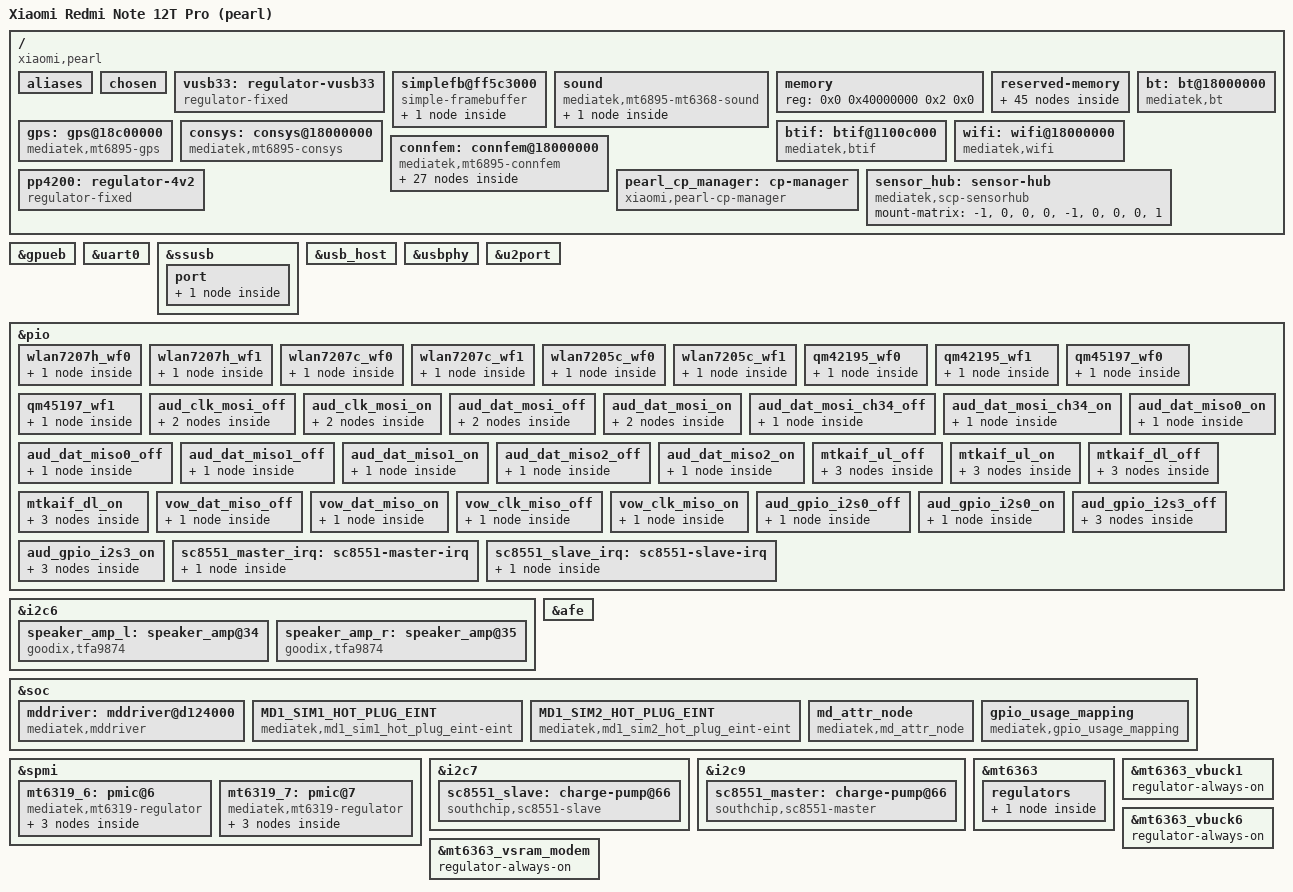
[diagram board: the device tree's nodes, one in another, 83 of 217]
// SPDX-License-Identifier: GPL-2.0 OR MIT
/*
 * MediaTek MT6896 (Dimensity 8200) Xiaomi Redmi Note 12T Pro board.
 * The DTS keeps the mt6895 platform-family naming used by its siblings.
 *
 * Codename: pearl (Xiaomi Redmi Note 12T Pro).
 *
 * Reserved-memory, regulators and rails follow the captured bootloader (LK) layout;
 * the embedded DTB replaces LK's but the memory map must stay identical.
 */

/dts-v1/;
#include "mt6895.dtsi"
#include <dt-bindings/input/input.h>
#include <dt-bindings/gpio/gpio.h>

/ {
	model = "Xiaomi Redmi Note 12T Pro (pearl)";
	chassis-type = "handset";
	compatible = "xiaomi,pearl", "mediatek,mt6895";

	#address-cells = <2>;
	#size-cells = <2>;

	aliases {
		serial0 = &uart0;
		/* match stock bus numbering so mt6375 etc. land on i2c-5 */
		i2c1 = &i2c1;
		i2c5 = &i2c5;
		i2c6 = &i2c6;
		i2c7 = &i2c7;
		i2c9 = &i2c9;
	};

	chosen {
		/*
		 * PEARL cmdline: setup.c re-reads /chosen/bootargs from THIS
		 * embedded DTB (early_init_dt_scan_chosen) because LK passes its
		 * own baked-in cmdline (setup_machine_fdt captured it before the
		 * DTB override) and ignores boot.img / vendor_boot cmdlines.
		 * printk.devkmsg=on: /dev/kmsg writes default to a 10-per-5s
		 * ratelimit that was silently dropping cinit's bursty GPT/diag
		 * output (also patched in kernel/printk/printk.c default).
		 * NOTE: console=ttyGS0 is DELIBERATELY absent — its CON_PRINTBUFFER
		 * console kept replaying the whole ring (USB re-enumeration),
		 * looping the log and stalling boot. The cinit shell still works
		 * (it writes directly to /dev/ttyGS0, no console param needed).
		 */
		bootargs = "8250.nr_uarts=4 clk_ignore_unused console=tty0 printk.devkmsg=on log_buf_len=2M";
		/*
		 * LK injects this tag into its FDT; our embedded-DTB override would
		 * lose it. Values dumped from the working Android device:
		 * struct tag_videolfb { u64 fb_base; u32 islcmfound; u32 fps;
		 *                      u32 vram; char lcmname[]; } (LE)
		 * fb_base=0xfe14f000 (framebuffer region start), islcmfound=1,
		 * fps=6060 (x100), vram=0x1eb0000, lcmname="l16_36_02_0b_dsc_vdo_lcm_drv".
		 * Without it, mtk_crtc_fill_fb_para() fails and the LK framebuffer is
		 * never inserted into the display IOMMU -> OVL fetch fault -> RDMA
		 * underflow -> display pipeline stalls after the LK frame.
		 */
		atag,videolfb = [00 f0 14 fe 00 00 00 00 01 00 00 00 ac 17 00 00
				 00 00 eb 01 6c 31 36 5f 33 36 5f 30 32 5f 30 62
				 5f 64 73 63 5f 76 64 6f 5f 6c 63 6d 5f 64 72 76
				 00 60 ff 50];
	};

	/* USB gadget 3.3V rail (mtu3 requires vusb33-supply; LK powers it) */
	vusb33: regulator-vusb33 {
		compatible = "regulator-fixed";
		regulator-name = "vusb33";
		regulator-min-microvolt = <3300000>;
		regulator-max-microvolt = <3300000>;
		regulator-always-on;
	};

	/*
	 * simple-framebuffer left behind by LK. Placed at root level (not under
	 * /chosen) because LK rewrites /chosen and would drop it.
	 * Address = the actual LK scanout layer (mt_disp_config_fb_layer =
	 * 0xff5c3000), which sits inside the reserved mblock-12-framebuffer
	 * region (0xfe14f000..0xfffff000). fbcon draws into the live LK buffer.
	 */
	simplefb@ff5c3000 {
		compatible = "simple-framebuffer";
		/* frame = stride(4352) * height(2460) = 0xa35c00; stays inside the
		 * no-map mblock-12-framebuffer region (0xfe14f000..0xfffff000) */
		reg = <0x0 0xff5c3000 0x0 0xa3c000>;
		width = <1080>;
		height = <2460>;
		stride = <(1088 * 4)>;
		format = "a8r8g8b8";
		panel = <&fb_panel>;

		fb_panel: fb-panel {
			width-mm = <75>;
			height-mm = <166>;
		};
	};

	sound {
		compatible = "mediatek,mt6895-mt6368-sound";
		mediatek,platform = <&afe>;
		mediatek,headset-codec = <&mt6368codec>;
		/* I2S3 out to smart amps; I2S0 echo reference in */
		mediatek,spk-i2s = <3 9>;

		mediatek,speaker-codec {
			sound-dai = <&speaker_amp_l>, <&speaker_amp_r>;
		};
	};

	memory {
		device_type = "memory";
		reg = <0x0 0x40000000 0x2 0x0>;
	};

	reserved-memory {
		#address-cells = <2>;
		#size-cells = <2>;
		ranges;

		/*
		 * Full MT6895 reserved-memory layout, taken verbatim from the
		 * live device tree (/sys/firmware/fdt) of the running stock
		 * Android build. These regions are owned by ATF/TEE/SCP/SSPM,
		 * modem, GPU and the display; the kernel MUST NOT allocate from
		 * them or early boot crashes on memory corruption.
		 */

		wifi_reserved: mblock-45-shared-dma-pool_wifi-reserve-memory_dma {
			reg = <0x00 0xbd000000 0x00 0x1400000>;
			no-map;
			compatible = "shared-dma-pool";
		};
		consys_reserved: mblock-44-consys_emi_reserved {
			reg = <0x00 0x8e500000 0x00 0x800000>;
			no-map;
			compatible = "mediatek,consys_emi_reserved";
		};
		mblock-43-sspm_ap-shared {
			reg = <0x00 0x7c4f0000 0x00 0x110000>;
			no-map;
			compatible = "mediatek,sspm_ap-shared";
		};
		mblock-42-consys_gps_emi {
			reg = <0x00 0x7cf00000 0x00 0x100000>;
			no-map;
			compatible = "mediatek,consys_gps_emi";
		};
		mblock-41-adsp_shared_reserved {
			reg = <0x00 0xf8000000 0x00 0x660000>;
			no-map;
			compatible = "mediatek,adsp_shared_reserved";
		};
		mblock-40-me_vcp_reserved {
			reg = <0x00 0xbee00000 0x00 0x800000>;
			no-map;
			compatible = "mediatek,me_vcp_reserved";
		};
		mblock-39-me_GPUmputab_PMA {
			reg = <0x00 0x78c00000 0x00 0x1400000>;
			no-map;
			compatible = "mediatek,me_GPUmputab_PMA";
		};
		mblock-38-me_GPUEB_SHARED {
			reg = <0x00 0x7c600000 0x00 0x200000>;
			no-map;
			compatible = "mediatek,me_GPUEB_SHARED";
		};
		mblock-37-adsp_image_reserved {
			reg = <0x00 0x7a000000 0x00 0x1230000>;
			no-map;
			compatible = "mediatek,adsp_image_reserved";
		};
		mblock-36-ap_md_c_smem {
			reg = <0x00 0x8a000000 0x00 0x2360000>;
			no-map;
			compatible = "mediatek,ap_md_c_smem";
		};
		mblock-35-ap_md_nc_smem {
			reg = <0x00 0x8e000000 0x00 0x120000>;
			no-map;
			compatible = "mediatek,ap_md_nc_smem";
		};
		mblock-34-md_mem_usage {
			reg = <0x00 0xed6e0000 0x00 0x920000>;
			no-map;
			compatible = "mediatek,md_mem_usage";
		};
		mblock-33-md_mem_usage {
			reg = <0x00 0xd4000000 0x00 0x7870000>;
			no-map;
			compatible = "mediatek,md_mem_usage";
		};
		mblock-32-md_mem_usage {
			reg = <0x00 0xd3000000 0x00 0x240000>;
			no-map;
			compatible = "mediatek,md_mem_usage";
		};
		mblock-31-md_mem_usage {
			reg = <0x00 0xd0000000 0x00 0x2710000>;
			no-map;
			compatible = "mediatek,md_mem_usage";
		};
		mblock-30-ccci_tag_mem {
			reg = <0x00 0xbf6f0000 0x00 0x10000>;
			no-map;
			compatible = "mediatek,ccci_tag_mem";
		};
		mblock-29-apu_apusys-rv_aee-coredump {
			reg = <0x00 0x8ed90000 0x00 0x270000>;
			no-map;
			compatible = "mediatek,apu_apusys-rv_aee-coredump";
		};
		mblock-28-apu_apusys-rv_secure {
			reg = <0x00 0x8f900000 0x00 0x700000>;
			no-map;
			compatible = "mediatek,apu_apusys-rv_secure";
		};
		mblock-27-apu_mvpu_algo {
			reg = <0x00 0xbf700000 0x00 0x200000>;
			compatible = "mediatek,apu_mvpu_algo";
		};
		mblock-26-mm_ccu_reserved {
			reg = <0x00 0x80000000 0x00 0x100000>;
			no-map;
			compatible = "mediatek,mm_ccu_reserved";
		};
		mblock-25-reserve-memory-scp_share {
			reg = <0x00 0x8f000000 0x00 0x6a2000>;
			no-map;
			compatible = "mediatek,reserve-memory-scp_share";
		};
		mblock-24-SCP-reserved {
			reg = <0x00 0xbf900000 0x00 0x500000>;
			no-map;
			compatible = "mediatek,SCP-reserved";
		};
		mblock-23-platform-debug_dfdmcu_dump {
			reg = <0x00 0xfd000000 0x00 0x280000>;
			no-map;
			compatible = "mediatek,platform-debug_dfdmcu_dump";
		};
		mblock-22-crypto_hw {
			reg = <0x00 0x48401000 0x00 0x1000>;
			no-map;
			compatible = "mediatek,crypto_hw";
		};
		mblock-21-security_tee_ree {
			reg = <0x02 0x3f000000 0x00 0xc00000>;
			no-map;
			compatible = "mediatek,security_tee_ree";
		};
		mblock-20-security_tee_log {
			reg = <0x02 0x3fc00000 0x00 0x20000>;
			no-map;
			compatible = "mediatek,security_tee_log";
		};
		mblock-19-tee-reserved {
			reg = <0x00 0x70000000 0x00 0x6000000>;
			no-map;
			compatible = "mediatek,tee-reserved";
		};
		mblock-18-tee-secmem {
			reg = <0x00 0x7c800000 0x00 0x700000>;
			no-map;
			compatible = "mediatek,tee-secmem";
		};
		mblock-17-MCUPM-reserved {
			reg = <0x00 0x7f300000 0x00 0x100000>;
			no-map;
			compatible = "mediatek,MCUPM-reserved";
		};
		mblock-16-SSPM-reserved {
			reg = <0x00 0x7fe3f000 0x00 0x180000>;
			no-map;
			compatible = "mediatek,SSPM-reserved";
		};
		mblock-15-BL31-reserved {
			reg = <0x00 0x48200000 0x00 0x200000>;
			no-map;
			compatible = "mediatek,BL31-reserved";
		};
		mblock-14-platform_mtksmmu_protpgd {
			reg = <0x00 0x7d000000 0x00 0x2200000>;
			no-map;
			compatible = "mediatek,platform_mtksmmu_protpgd";
		};
		mblock-13-me_cmdq_reserved {
			reg = <0x02 0x3fe00000 0x00 0x100000>;
			no-map;
			compatible = "mediatek,me_cmdq_reserved";
		};
		mblock-12-framebuffer {
			reg = <0x00 0xfe14f000 0x00 0x1eb0000>;
			/*
			 * no-map: this region (which contains the live LK scanout
			 * framebuffer at 0xff5c3000) must be excluded from the
			 * kernel's RAM map. Otherwise simplefb's
			 * request_mem_region()/ioremap() fail (-ENOMEM, "cannot
			 * reserve video memory" / ioremap_p2p WARN).
			 */
			no-map;
			compatible = "mediatek,framebuffer";
		};
		mblock-11-aee_lk {
			reg = <0x00 0x50700000 0x00 0x800000>;
			compatible = "mediatek,aee_lk";
		};
		mblock-10-minirdump {
			reg = <0x00 0x48170000 0x00 0x10000>;
			no-map;
			compatible = "mediatek,minirdump";
		};
		mblock-8-aee_debug_kinfo {
			reg = <0x00 0x48080000 0x00 0x10000>;
			no-map;
			compatible = "mediatek,aee_debug_kinfo";
		};
		mblock-7-atf-log-reserved {
			reg = <0x00 0xbfe00000 0x00 0x200000>;
			no-map;
			compatible = "mediatek,atf-log-reserved";
		};
		mblock-6-log_store {
			reg = <0x00 0x7ffbf000 0x00 0x40000>;
			compatible = "mediatek,log_store";
		};
		mblock-5-gz-log {
			reg = <0x00 0x7f200000 0x00 0x41000>;
			compatible = "mediatek,gz-log";
		};
		mblock-4-unmap2 {
			reg = <0x00 0x7f400000 0x00 0x400000>;
			no-map;
			compatible = "mediatek,unmap2";
		};
		mblock-3-gz {
			reg = <0x00 0x7f800000 0x00 0x600000>;
			no-map;
			compatible = "mediatek,gz";
		};
		mblock-2-emi_mbist_buf {
			reg = <0x00 0x7ffff000 0x00 0x1000>;
			no-map;
			compatible = "mediatek,emi_mbist_buf";
		};
		mblock-1-dramc-rk0 {
			reg = <0x02 0x3fffe000 0x00 0x2000>;
			no-map;
			compatible = "mediatek,dramc-rk0";
		};
		/* pstore/ramoops, matches the downstream Android config */
		ramoops@48090000 {
			compatible = "ramoops";
			reg = <0x00 0x48090000 0x00 0xe0000>;
			record-size = <0x20000>;
			console-size = <0x40000>;
			pmsg-size = <0x10000>;
			ecc-size = <0>;
			no-map;
		};
	};

	/* GPS (GNSS) —— 连接子系统（MT6637 a-die）里的 GPS 引擎。
	 * 数值来源：厂商 mt6895.dts 的 gps@18c00000；emi-addr 用 pearl 自己的
	 * mblock-42-consys_gps_emi（0x7cf00000, 1MiB）——LK 不会改写我们的内嵌 DTB，
	 * 所以 emi-addr 必须写死，不能像厂商那样留 0。
	 * 中断 528..534 与对照机 yuechu（同代 MT6895）完全一致。
	 */
	gps: gps@18c00000 {
		compatible = "mediatek,mt6895-gps";
		reg = <0x00 0x18000000 0x00 0x100000>,
		      <0x00 0x18c00000 0x00 0x100000>,
		      <0x00 0x1c000000 0x00 0x4>,
		      <0x00 0x1c805028 0x00 0x4>,
		      <0x00 0x1c805030 0x00 0x4>,
		      <0x00 0x1c8050cc 0x00 0x28>;
		reg-names = "conn_infra_base", "conn_gps_base",
			    "status_dummy_cr", "tia2_gps_on",
			    "tia2_gps_rc_sel", "tia2_gps_debug";
		interrupt-parent = <&gic>;
		interrupts = <GIC_SPI 528 IRQ_TYPE_LEVEL_HIGH 0>,
			     <GIC_SPI 529 IRQ_TYPE_LEVEL_HIGH 0>,
			     <GIC_SPI 530 IRQ_TYPE_LEVEL_HIGH 0>,
			     <GIC_SPI 531 IRQ_TYPE_LEVEL_HIGH 0>,
			     <GIC_SPI 532 IRQ_TYPE_LEVEL_HIGH 0>,
			     <GIC_SPI 533 IRQ_TYPE_LEVEL_HIGH 0>,
			     <GIC_SPI 534 IRQ_TYPE_LEVEL_HIGH 0>;
		emi-connac-ver = <2>;
		emi-addr = <0x7cf00000>;
		emi-size = <0x100000>;
		emi-alignment = <0x100000>;
		emi-max-addr = <0x80000000>;
		status = "okay";
	};

	/* MediaTek CONNAC2X2 SOC7_0 connectivity: consys / wifi / connfem.
	 * Nodes and properties copied from downstream mt6895.dts and
	 * cust_mt6895_connfem.dtsi.  memory-region references are added so the
	 * downstream fullmac driver can find the reserved EMI/DMA areas without
	 * depending on LK runtime fixups.
	 */
	consys: consys@18000000 {
		compatible = "mediatek,mt6895-consys";
		#thermal-sensor-cells = <0>;
		reg = <0x00 0x10001000 0x00 0xee4 0x00 0x10005000 0x00 0xa78
		       0x00 0x11c30000 0x00 0xa14 0x00 0x11ea0000 0x00 0xa04
		       0x00 0x18000000 0x00 0x470 0x00 0x18001000 0x00 0x658
		       0x00 0x18003000 0x00 0x204 0x00 0x1800e000 0x00 0x124
		       0x00 0x18011000 0x00 0x138 0x00 0x18012000 0x00 0x98
		       0x00 0x18020000 0x00 0x4c 0x00 0x18023000 0x00 0xe28
		       0x00 0x1803b000 0x00 0x18 0x00 0x18040000 0x00 0x2c
		       0x00 0x18041000 0x00 0x128 0x00 0x18042000 0x00 0x324
		       0x00 0x1804b000 0x00 0x414 0x00 0x1804d000 0x00 0x41c
		       0x00 0x1804f000 0x00 0x148 0x00 0x18053800 0x00 0x1000
		       0x00 0x18060000 0x00 0xc08 0x00 0x18070000 0x00 0x8004
		       0x00 0x1c001000 0x00 0xfb0 0x00 0x1c007000 0x00 0x51c>;
		power-domains = <&spm MT6895_POWER_DOMAIN_CONN>;
		mt6363_vcn13-supply = <&mt6363_vcn13>;
		mt6363_vrfio18-supply = <&mt6363_vrfio18>;
		mt6368_vcn33_1-supply = <&mt6368_vcn33_1>;
		mt6368_vcn33_2-supply = <&mt6368_vcn33_2>;
		mt6368_vant18-supply = <&mt6368_vant18>;
		memory-region = <&consys_reserved>;
		emi-addr = <0>;
		emi-size = <0x7e0000>;
		emi-alignment = <0x100000>;
		emi-max-addr = <0x90000000>;
		tcxo_support = "false";
		scp-shm-addr = <0>;
		scp-shm-size = <0x20000>;
		status = "okay";
	};


	btif: btif@1100c000 {
		compatible = "mediatek,btif";
		reg = <0x0 0x1100c000 0x0 0x100>,
		      <0x0 0x11300b00 0x0 0x80>,
		      <0x0 0x11300b80 0x0 0x80>;
		interrupts = <GIC_SPI 202 IRQ_TYPE_LEVEL_HIGH 0>,
			     <GIC_SPI 179 IRQ_TYPE_LEVEL_HIGH 0>,
			     <GIC_SPI 180 IRQ_TYPE_LEVEL_HIGH 0>;
		clocks = <&pericfg_ao CLK_PERAOP_0_BTIF>,
			 <&pericfg_ao CLK_PERAOP_1_DMA_BCLK>;
		clock-names = "btifc", "apdmac";
		status = "okay";
	};

	wifi: wifi@18000000 {
		compatible = "mediatek,wifi";
		reg = <0x0 0x18000000 0x0 0x700000>;
		interrupts = <GIC_SPI 522 IRQ_TYPE_LEVEL_HIGH 0>,
			     <GIC_SPI 537 IRQ_TYPE_LEVEL_HIGH 0>;
		memory-region = <&wifi_reserved>;
		flavor_bin = "b_t";
		emi-addr = <0>;
		emi-size = <0x1400000>;
		emi-alignment = <0x1000000>;
		emi-max-addr = <0xC0000000>;
		status = "okay";
	};


	bt: bt@18000000 {
		compatible = "mediatek,bt";
		flavor_bin = "b_t";
		reg = <0x0 0x18000000 0x0 0x1000>,
		      <0x0 0x18001000 0x0 0x1000>,
		      <0x0 0x18051000 0x0 0x1000>,
		      <0x0 0x18060000 0x0 0x1000>,
		      <0x0 0x18800000 0x0 0x1000>,
		      <0x0 0x18812000 0x0 0x1000>,
		      <0x0 0x10001000 0x0 0x1000>;
		interrupts = <GIC_SPI 523 IRQ_TYPE_LEVEL_HIGH 0>,
			     <GIC_SPI 538 IRQ_TYPE_LEVEL_HIGH 0>,
			     <GIC_SPI 524 IRQ_TYPE_LEVEL_HIGH 0>;
		status = "okay";
	};

	connfem: connfem@18000000 {
		compatible = "mediatek,mt6895-connfem";
		pinctrl-names = "wlan7207h_wlan7207c",
				"wlan7207h_wlan7205c",
				"qm42195_qm45197";
		pinctrl-0 = <&wlan7207h_wf0>, <&wlan7207h_wf1>,
			    <&wlan7207c_wf0>, <&wlan7207c_wf1>;
		pinctrl-1 = <&wlan7207h_wf0>, <&wlan7207h_wf1>,
			    <&wlan7205c_wf0>, <&wlan7205c_wf1>;
		pinctrl-2 = <&qm42195_wf0>, <&qm42195_wf1>,
			    <&qm45197_wf0>, <&qm45197_wf1>;
		status = "okay";

		epa_elna_mtk {
			parts = <&nofem &nofem>,
				<&wlan7207h &wlan7207c>,
				<&wlan7207h &wlan7207c>,
				<&wlan7207h &wlan7207c>,
				<&wlan7207h &wlan7207c>,
				<&wlan7207h &wlan7205c>,
				<&wlan7207h &wlan7205c>,
				<&wlan7207h &wlan7205c>,
				<&wlan7207h &wlan7205c>,
				<&qm42195 &qm45197>,
				<&qm42195 &qm45197>,
				<&qm42195 &qm45197>,
				<&qm42195 &qm45197>;

			bt {
				flags-12 { epa_elna; };
				flags-11 { bypass; };
				flags-10 { epa_elna; };
				flags-9 { bypass; };
				flags-8 { epa_elna; };
				flags-7 { bypass; };
				flags-6 { epa_elna; };
				flags-5 { bypass; };
				flags-4 { epa_elna; };
				flags-3 { bypass; };
				flags-2 { epa_elna; };
				flags-1 { bypass; };
			};

			wifi {
				flags-10 { open-loop; };
				flags-9 { open-loop; };
				flags-6 { open-loop; };
				flags-5 { open-loop; };
				flags-2 { open-loop; };
				flags-1 { open-loop; };
			};
		};

		nofem: nofem {
			vid = <0>;
			pid = <0>;
		};

		wlan7207h: wlan7207h {
			vid = <2>;
			pid = <4>;
		};

		wlan7205c: wlan7205c {
			vid = <2>;
			pid = <5>;
		};

		wlan7207c: wlan7207c {
			vid = <2>;
			pid = <7>;
		};

		qm42195: qm42195 {
			vid = <3>;
			pid = <1>;
		};

		qm45197: qm45197 {
			vid = <3>;
			pid = <2>;
		};
	};
};

/* GPUEB shared memory: the live FDT reserves 2MB at 0x7c600000 as
 * mblock-38-me_GPUEB_SHARED. gpueb_reserved_mem.c can use it directly
 * when gpueb_mem_addr/size are present on the gpueb node.
 */
&gpueb {
	gpueb_mem_addr = <0x0 0x7c600000>;
	gpueb_mem_size = <0x0 0x200000>;
};

&uart0 {
	status = "okay";
};

/*
 * The mediatek_v2 display driver (binds on dispsys_config@14000000) is now
 * active. The LK frame stays visible via simplefb above until the DRM driver
 * takes over. Keep simplefb enabled during bring-up as a fallback.
 */

/*
 * USB manual OTG:
 * - dr_mode="otg" keeps both host and device paths available.
 * - usb-role-switch + role-switch-default-mode="device" expose a sysfs role
 *   switch for manual host/device selection (no automatic Type-C detect yet).
 * - vbus-supply is the MT6375 charger OTG regulator needed to source 5V in
 *   host mode.
 * - The t-phy software role switch is kept, and role-switch-default-mode="device"
 *   is set on the xHCI node so the PHY initializes in device mode.
 */

&ssusb {
	status = "okay";
	dr_mode = "otg";
	maximum-speed = "high-speed";
	usb-role-switch;
	role-switch-default-mode = "peripheral";
	vusb33-supply = <&vusb33>;
	vbus-supply = <&otg_vbus>;
	/* PEARL: no VBUS detect pin on pearl, force it in software */
	mediatek,force-vbus;

	port {
		mtu3_hs_role_sw: endpoint {
			remote-endpoint = <&typec_con_hs>;
		};
	};
};

&usb_host {
	status = "okay";
	role-switch-default-mode = "peripheral";
	vusb33-supply = <&vusb33>;
};

&usbphy {
	status = "okay";
};

&u2port {
	status = "okay";
	/* PHY tuning from downstream pearl DTS */
	mediatek,eye-vrt = <0x03>;
	mediatek,eye-term = <0x03>;
	mediatek,discth = <0x0b>;
};

/* ConnFem ANTSEL pinmux and FEM function mapping */
&pio {
	wlan7207h_wf0: wlan7207h_wf0 {
		pins_cmd_dat {
			pinmux = <PINMUX_GPIO176__FUNC_ANT_SEL0>,
				<PINMUX_GPIO177__FUNC_ANT_SEL1>,
				<PINMUX_GPIO178__FUNC_ANT_SEL2>,
				<PINMUX_GPIO179__FUNC_ANT_SEL3>;
			mapping = <0 3 0>,	/* ANTSEL 0 <-> PIN #3: C0 */
				<1 2 0>,	/* ANTSEL 1 <-> PIN #2: C1 */
				<2 4 0>,	/* ANTSEL 2 <-> PIN #4: C2 */
				<3 11 0>;	/* ANTSEL 3 <-> VCTRL */
		};
	};

	wlan7207h_wf1: wlan7207h_wf1 {
		pins_cmd_dat {
			pinmux = <PINMUX_GPIO184__FUNC_ANT_SEL8>,
				<PINMUX_GPIO185__FUNC_ANT_SEL9>,
				<PINMUX_GPIO188__FUNC_ANT_SEL10>;
			mapping = <8 0x83 0>,	/* ANTSEL  8 <-> PIN #3: C0 */
				<9 0x82 0>,	/* ANTSEL  9 <-> PIN #2: C1 */
				<10 0x84 0>;	/* ANTSEL 10 <-> PIN #4: C2 */
		};
	};

	wlan7207c_wf0: wlan7207c_wf0 {
		pins_cmd_dat {
			pinmux = <PINMUX_GPIO180__FUNC_ANT_SEL4>,
				<PINMUX_GPIO76__FUNC_ANT_SEL20>,
				<PINMUX_GPIO182__FUNC_ANT_SEL6>,
				<PINMUX_GPIO183__FUNC_ANT_SEL7>;
			mapping = <4 0x4A 0>,	/* ANTSEL  4 <-> PIN #12: C0 */
				<20 0x4B 0>,	/* ANTSEL 20 <-> PIN #13: C1 */
				<6 0x4C 0>,	/* ANTSEL  6 <-> PIN #14: C2 */
				<7 0x41 0>;	/* ANTSEL  7 <-> PIN #11: C3 */
		};
	};

	wlan7207c_wf1: wlan7207c_wf1 {
		pins_cmd_dat {
			pinmux = <PINMUX_GPIO189__FUNC_ANT_SEL11>,
				<PINMUX_GPIO77__FUNC_ANT_SEL21>,
				<PINMUX_GPIO190__FUNC_ANT_SEL12>,
				<PINMUX_GPIO181__FUNC_ANT_SEL5>;
			mapping = <11 0xCA 0>,	/* ANTSEL 11 <-> PIN #12: C0 */
				<21 0xCB 0>,	/* ANTSEL 21 <-> PIN #13: C1 */
				<12 0xCC 0>,	/* ANTSEL 12 <-> PIN #14: C2 */
				<5 0xC1 0>;	/* ANTSEL  5 <-> PIN #11: C3 */
		};
	};

	wlan7205c_wf0: wlan7205c_wf0 {
		pins_cmd_dat {
			pinmux = <PINMUX_GPIO180__FUNC_ANT_SEL4>,
				<PINMUX_GPIO76__FUNC_ANT_SEL20>,
				<PINMUX_GPIO182__FUNC_ANT_SEL6>,
				<PINMUX_GPIO183__FUNC_ANT_SEL7>;
			mapping = <4 0x4C 0>,	/* ANTSEL  4 <-> PIN #12: C0 */
				<20 0x4D 0>,	/* ANTSEL 20 <-> PIN #13: C1 */
				<6 0x4E 0>,	/* ANTSEL  6 <-> PIN #14: C2 */
				<7 0x4B 0>;	/* ANTSEL  7 <-> PIN #11: C3 */
		};
	};

	wlan7205c_wf1: wlan7205c_wf1 {
		pins_cmd_dat {
			pinmux = <PINMUX_GPIO189__FUNC_ANT_SEL11>,
				<PINMUX_GPIO77__FUNC_ANT_SEL21>,
				<PINMUX_GPIO190__FUNC_ANT_SEL12>,
				<PINMUX_GPIO181__FUNC_ANT_SEL5>;
			mapping = <11 0xCC 0>,	/* ANTSEL 11 <-> PIN #12: C0 */
				<21 0xCD 0>,	/* ANTSEL 21 <-> PIN #13: C1 */
				<12 0xCE 0>,	/* ANTSEL 12 <-> PIN #14: C2 */
				<5 0xCB 0>;	/* ANTSEL  5 <-> PIN #11: C3 */
		};
	};

	qm42195_wf0: qm42195_wf0 {
		pins_cmd_dat {
			pinmux = <PINMUX_GPIO176__FUNC_ANT_SEL0>,
				<PINMUX_GPIO177__FUNC_ANT_SEL1>,
				<PINMUX_GPIO178__FUNC_ANT_SEL2>,
				<PINMUX_GPIO179__FUNC_ANT_SEL3>;
			mapping = <0 3 0>,	/* ANTSEL 0 <-> PIN #3: PAEN */
				<1 2 0>,	/* ANTSEL 1 <-> PIN #2: LNAEN */
				<2 4 0>,	/* ANTSEL 2 <-> PIN #4: BTEN */
				<3 11 0>;	/* ANTSEL 3 <-> VCTRL */
		};
	};

	qm42195_wf1: qm42195_wf1 {
		pins_cmd_dat {
			pinmux = <PINMUX_GPIO184__FUNC_ANT_SEL8>,
				<PINMUX_GPIO185__FUNC_ANT_SEL9>,
				<PINMUX_GPIO188__FUNC_ANT_SEL10>;
			mapping = <8 0x83 0>,	/* ANTSEL  8 <-> PIN #3: PAEN */
				<9 0x82 0>,	/* ANTSEL  9 <-> PIN #2: LNAEN */
				<10 0x84 0>;	/* ANTSEL 10 <-> PIN #4: BTEN */
		};
	};

	qm45197_wf0: qm45197_wf0 {
		pins_cmd_dat {
			pinmux = <PINMUX_GPIO180__FUNC_ANT_SEL4>,
				<PINMUX_GPIO76__FUNC_ANT_SEL20>,
				<PINMUX_GPIO182__FUNC_ANT_SEL6>;
			mapping = <4 0x4A 0>,	/* ANTSEL  4 <-> PIN #10: PAEN */
				<20 0x4B 0>,	/* ANTSEL 20 <-> PIN #11: LNAEN */
				<6 0x4C 0>;	/* ANTSEL  6 <-> PIN #12: SEL3 */
		};
	};

	qm45197_wf1: qm45197_wf1 {
		pins_cmd_dat {
			pinmux = <PINMUX_GPIO189__FUNC_ANT_SEL11>,
				<PINMUX_GPIO77__FUNC_ANT_SEL21>,
				<PINMUX_GPIO190__FUNC_ANT_SEL12>;
			mapping = <11 0xCA 0>,	/* ANTSEL 11 <-> PIN #10: PAEN */
				<21 0xCB 0>,	/* ANTSEL 21 <-> PIN #11: LNAEN */
				<12 0xCC 0>;	/* ANTSEL 12 <-> PIN #12: SEL3 */
		};
	};
};

/* TFA9874 smart amplifiers (Goodix), shared reset, I2S3 data */
&i2c6 {
speaker_amp_l: speaker_amp@34 {
compatible = "goodix,tfa9874";
reg = <0x34>;
#sound-dai-cells = <0>;
sound-name-prefix = "Left";
reset-gpio = <&pio 213 GPIO_ACTIVE_HIGH>;
irq-gpio = <&pio 19 GPIO_ACTIVE_HIGH>;
spk-sw-gpio = <&pio 160 GPIO_ACTIVE_HIGH>;
status = "okay";
};

speaker_amp_r: speaker_amp@35 {
compatible = "goodix,tfa9874";
reg = <0x35>;
#sound-dai-cells = <0>;
sound-name-prefix = "Right";
reset-gpio = <&pio 213 GPIO_ACTIVE_HIGH>;
irq-gpio = <&pio 15 GPIO_ACTIVE_HIGH>;
status = "okay";
};
};

/* Audio AFE pinmux / pinctrl states (from downstream xiaomi-mt6895-common.dtsi) */
&afe {
pinctrl-names = "aud_clk_mosi_off",
"aud_clk_mosi_on",
"aud_dat_mosi_off",
"aud_dat_mosi_on",
"aud_dat_mosi_ch34_off",
"aud_dat_mosi_ch34_on",
"aud_dat_miso0_off",
"aud_dat_miso0_on",
"aud_dat_miso1_off",
"aud_dat_miso1_on",
"aud_dat_miso2_off",
"aud_dat_miso2_on",
"vow_dat_miso_off",
"vow_dat_miso_on",
"vow_clk_miso_off",
"vow_clk_miso_on",
"aud_gpio_i2s3_off",
"aud_gpio_i2s3_on",
"aud_gpio_i2s0_off",
"aud_gpio_i2s0_on",
"mtkaif_ul_off",
"mtkaif_ul_on",
"mtkaif_dl_off",
"mtkaif_dl_on";
pinctrl-0 = <&aud_clk_mosi_off>;
pinctrl-1 = <&aud_clk_mosi_on>;
pinctrl-2 = <&aud_dat_mosi_off>;
pinctrl-3 = <&aud_dat_mosi_on>;
pinctrl-4 = <&aud_dat_mosi_ch34_off>;
pinctrl-5 = <&aud_dat_mosi_ch34_on>;
pinctrl-6 = <&aud_dat_miso0_off>;
pinctrl-7 = <&aud_dat_miso0_on>;
pinctrl-8 = <&aud_dat_miso1_off>;
pinctrl-9 = <&aud_dat_miso1_on>;
pinctrl-10 = <&aud_dat_miso2_off>;
pinctrl-11 = <&aud_dat_miso2_on>;
pinctrl-12 = <&vow_dat_miso_off>;
pinctrl-13 = <&vow_dat_miso_on>;
pinctrl-14 = <&vow_clk_miso_off>;
pinctrl-15 = <&vow_clk_miso_on>;
pinctrl-16 = <&aud_gpio_i2s3_off>;
pinctrl-17 = <&aud_gpio_i2s3_on>;
pinctrl-18 = <&aud_gpio_i2s0_off>;
pinctrl-19 = <&aud_gpio_i2s0_on>;
pinctrl-20 = <&mtkaif_ul_off>;
pinctrl-21 = <&mtkaif_ul_on>;
pinctrl-22 = <&mtkaif_dl_off>;
pinctrl-23 = <&mtkaif_dl_on>;
};

&pio {
aud_clk_mosi_off: aud_clk_mosi_off {
pins_cmd1_dat {
pinmux = <PINMUX_GPIO202__FUNC_GPIO202>;
input-enable;
bias-pull-down;
};
pins_cmd2_dat {
pinmux = <PINMUX_GPIO203__FUNC_GPIO203>;
input-enable;
bias-pull-down;
};
};

aud_clk_mosi_on: aud_clk_mosi_on {
pins_cmd1_dat {
pinmux = <PINMUX_GPIO202__FUNC_AUD_CLK_MOSI>;
input-schmitt-enable;
bias-disable;
};
pins_cmd2_dat {
pinmux = <PINMUX_GPIO203__FUNC_AUD_SYNC_MOSI>;
input-schmitt-enable;
bias-disable;
};
};

aud_dat_mosi_off: aud_dat_mosi_off {
pins_cmd1_dat {
pinmux = <PINMUX_GPIO204__FUNC_GPIO204>;
input-enable;
bias-pull-down;
};
pins_cmd2_dat {
pinmux = <PINMUX_GPIO205__FUNC_GPIO205>;
input-enable;
bias-pull-down;
};
};

aud_dat_mosi_on: aud_dat_mosi_on {
pins_cmd1_dat {
pinmux = <PINMUX_GPIO204__FUNC_AUD_DAT_MOSI0>;
input-schmitt-enable;
bias-disable;
};
pins_cmd2_dat {
pinmux = <PINMUX_GPIO205__FUNC_AUD_DAT_MOSI1>;
input-schmitt-enable;
bias-disable;
};
};

aud_dat_mosi_ch34_off: aud_dat_mosi_ch34_off {
pins_cmd1_dat {
pinmux = <PINMUX_GPIO206__FUNC_GPIO206>;
input-enable;
bias-pull-down;
};
};

aud_dat_mosi_ch34_on: aud_dat_mosi_ch34_on {
pins_cmd1_dat {
pinmux = <PINMUX_GPIO206__FUNC_AUD_DAT_MOSI2>;
input-schmitt-enable;
bias-disable;
};
};

aud_dat_miso0_off: aud_dat_miso0_off {
pins_cmd1_dat {
pinmux = <PINMUX_GPIO209__FUNC_GPIO209>;
input-enable;
bias-pull-down;
};
};

aud_dat_miso0_on: aud_dat_miso0_on {
pins_cmd1_dat {
pinmux = <PINMUX_GPIO209__FUNC_AUD_DAT_MISO0>;
input-schmitt-enable;
bias-disable;
};
};

aud_dat_miso1_off: aud_dat_miso1_off {
pins_cmd1_dat {
pinmux = <PINMUX_GPIO210__FUNC_GPIO210>;
input-enable;
bias-disable;
};
};

aud_dat_miso1_on: aud_dat_miso1_on {
pins_cmd1_dat {
pinmux = <PINMUX_GPIO210__FUNC_AUD_DAT_MISO1>;
input-schmitt-enable;
bias-disable;
};
};

aud_dat_miso2_off: aud_dat_miso2_off {
pins_cmd1_dat {
pinmux = <PINMUX_GPIO211__FUNC_GPIO211>;
input-enable;
bias-pull-down;
};
};

aud_dat_miso2_on: aud_dat_miso2_on {
pins_cmd1_dat {
pinmux = <PINMUX_GPIO211__FUNC_AUD_DAT_MISO2>;
input-schmitt-enable;
bias-disable;
};
};

/*
 * Combined MTKAIF states: pinctrl_select_state() is exclusive, so the
 * per-group states used downstream cannot be stacked one after another on
 * kernels where switching away actively restores released pins. Apply the
 * whole interface with a single state instead.
 */
mtkaif_ul_off: mtkaif_ul_off {
pins_clk {
pinmux = <PINMUX_GPIO202__FUNC_GPIO202>, <PINMUX_GPIO203__FUNC_GPIO203>;
input-enable;
bias-pull-down;
};
pins_dat {
pinmux = <PINMUX_GPIO209__FUNC_GPIO209>, <PINMUX_GPIO210__FUNC_GPIO210>;
input-enable;
bias-pull-down;
};
pins_dat_mosi {
pinmux = <PINMUX_GPIO204__FUNC_GPIO204>, <PINMUX_GPIO205__FUNC_GPIO205>,
	 <PINMUX_GPIO206__FUNC_GPIO206>;
input-enable;
bias-pull-down;
};
};

mtkaif_ul_on: mtkaif_ul_on {
pins_clk {
pinmux = <PINMUX_GPIO202__FUNC_AUD_CLK_MOSI>, <PINMUX_GPIO203__FUNC_AUD_SYNC_MOSI>;
input-schmitt-enable;
bias-disable;
};
pins_dat {
pinmux = <PINMUX_GPIO209__FUNC_AUD_DAT_MISO0>, <PINMUX_GPIO210__FUNC_AUD_DAT_MISO1>;
input-schmitt-enable;
bias-disable;
};
/* Keep the DL data lanes (incl. the wired MOSI2) alive so an UL request
 * cannot strip them from a concurrent playback stream. */
pins_dat_mosi {
pinmux = <PINMUX_GPIO204__FUNC_AUD_DAT_MOSI0>, <PINMUX_GPIO205__FUNC_AUD_DAT_MOSI1>,
	 <PINMUX_GPIO206__FUNC_AUD_DAT_MOSI2>;
input-schmitt-enable;
bias-disable;
};
};

mtkaif_dl_off: mtkaif_dl_off {
pins_clk {
pinmux = <PINMUX_GPIO202__FUNC_GPIO202>, <PINMUX_GPIO203__FUNC_GPIO203>;
input-enable;
bias-pull-down;
};
pins_dat {
pinmux = <PINMUX_GPIO204__FUNC_GPIO204>, <PINMUX_GPIO205__FUNC_GPIO205>;
input-enable;
bias-pull-down;
};
pins_dat_ch34 {
pinmux = <PINMUX_GPIO206__FUNC_GPIO206>;
input-enable;
bias-pull-down;
};
};

mtkaif_dl_on: mtkaif_dl_on {
pins_clk {
pinmux = <PINMUX_GPIO202__FUNC_AUD_CLK_MOSI>, <PINMUX_GPIO203__FUNC_AUD_SYNC_MOSI>;
input-schmitt-enable;
bias-disable;
};
pins_dat {
pinmux = <PINMUX_GPIO204__FUNC_AUD_DAT_MOSI0>, <PINMUX_GPIO205__FUNC_AUD_DAT_MOSI1>;
input-schmitt-enable;
bias-disable;
};
/* CH34/3rd-DAC downlink data lane; on pearl this pad is wired to the
 * codec's AIF data input and carries all DL frames to the MT6368. */
pins_dat_ch34 {
pinmux = <PINMUX_GPIO206__FUNC_AUD_DAT_MOSI2>;
input-schmitt-enable;
bias-disable;
};
};

vow_dat_miso_off: vow_dat_miso_off {
pins_cmd1_dat {
pinmux = <PINMUX_GPIO209__FUNC_GPIO209>;
input-enable;
bias-pull-down;
};
};

vow_dat_miso_on: vow_dat_miso_on {
pins_cmd1_dat {
pinmux = <PINMUX_GPIO209__FUNC_VOW_DAT_MISO>;
input-schmitt-enable;
bias-disable;
};
};

vow_clk_miso_off: vow_clk_miso_off {
pins_cmd1_dat {
pinmux = <PINMUX_GPIO210__FUNC_GPIO210>;
input-enable;
bias-pull-down;
};
};

vow_clk_miso_on: vow_clk_miso_on {
pins_cmd1_dat {
pinmux = <PINMUX_GPIO210__FUNC_VOW_CLK_MISO>;
input-schmitt-enable;
bias-disable;
};
};

aud_gpio_i2s0_off: aud_gpio_i2s0_off {
pins_cmd1_dat {
pinmux = <PINMUX_GPIO23__FUNC_GPIO23>;
input-enable;
bias-pull-down;
};
};

aud_gpio_i2s0_on: aud_gpio_i2s0_on {
pins_cmd1_dat {
pinmux = <PINMUX_GPIO23__FUNC_I2S0_DI>;
input-schmitt-enable;
bias-disable;
};
};

aud_gpio_i2s3_off: aud_gpio_i2s3_off {
pins_cmd1_dat {
pinmux = <PINMUX_GPIO21__FUNC_GPIO21>;
input-enable;
bias-pull-down;
};
pins_cmd2_dat {
pinmux = <PINMUX_GPIO22__FUNC_GPIO22>;
input-enable;
bias-pull-down;
};
pins_cmd3_dat {
pinmux = <PINMUX_GPIO24__FUNC_GPIO24>;
input-enable;
bias-pull-down;
};
};

aud_gpio_i2s3_on: aud_gpio_i2s3_on {
pins_cmd1_dat {
pinmux = <PINMUX_GPIO21__FUNC_I2S3_BCK>;
input-schmitt-enable;
bias-disable;
};
pins_cmd2_dat {
pinmux = <PINMUX_GPIO22__FUNC_I2S3_LRCK>;
input-schmitt-enable;
bias-disable;
};
pins_cmd3_dat {
pinmux = <PINMUX_GPIO24__FUNC_I2S3_DO>;
input-schmitt-enable;
bias-disable;
};
};
};

/*
 * Cellular modem (MD1) — AP-side CCCI interface.
 * The MD firmware itself is loaded by LK before the kernel boots; this node
 * only describes the AP<->MD control/data hardware for the vendor-derived
 * eccci driver. Values from Xiaomi-MT6896-OSS vendor mt6895.dts.
 */
&soc {
	mddriver: mddriver@d124000 {
		compatible = "mediatek,mddriver";
		reg = <0 0x0d124000 0 0x2000>;	/* MD L2SRAM */
		mediatek,mdhif_type = <6>;	/* CLDMA | DPMAIF */
		mediatek,md_id = <0>;
		mediatek,ap_plat_info = <6895>;
		mediatek,md_generation = <6298>;
		mediatek,offset_epon_md1 = <0x44 0x06>;
		mediatek,cldma_capability = <14>;
		mediatek,power_flow_config = <0x4>;
		mediatek,srclken_o1 = <0>;
		/*
		 * DTS/GIC_ID: MDWDT 253/285; CCIF0 241/273; CCIF0 242/274
		 * GIC_SPI cells take the SPI number, not the GIC ID (GIC ID =
		 * SPI + 32).  The old values here were the GIC IDs, which moved
		 * MD_WDT/CCIF0 32 lines up; the real CCIF lines stayed unmapped,
		 * so the AP never saw the MD's HS1 interrupt.
		 */
		interrupts = <GIC_SPI 253 IRQ_TYPE_LEVEL_HIGH 0>,
			     <GIC_SPI 241 IRQ_TYPE_LEVEL_HIGH 0>,
			     <GIC_SPI 242 IRQ_TYPE_LEVEL_HIGH 0>;
		power-domains = <&spm MT6895_POWER_DOMAIN_MD>;
		ccci-infracfg = <&infracfg_ao>;
		ccci-topckgen = <&topckgen>;
	};

	/*
	 * MD EINT descriptors - MOLY requests these via CCCI RPC right
	 * after processing the runtime data, before sending HS2. Without
	 * them the RPC reply carries no data and MOLY stalls.
	 */
	MD1_SIM1_HOT_PLUG_EINT {
		compatible = "mediatek,md1_sim1_hot_plug_eint-eint";
		debounce = <0 10000>;
		dedicated = <0 0>;
		interrupts = <0 8>;
		sockettype = <0 0>;
		src_pin = <0 1>;
		status = "okay";
	};

	MD1_SIM2_HOT_PLUG_EINT {
		compatible = "mediatek,md1_sim2_hot_plug_eint-eint";
		debounce = <1 10000>;
		dedicated = <1 0>;
		interrupts = <1 8>;
		sockettype = <1 0>;
		src_pin = <1 2>;
		status = "okay";
	};

	/*
	 * Vendor MD RPC attributes (DRDI RF set index for this MOLY build).
	 *
	 * md_drdi_rf_set_idx：MODEM 通过 CCCI RPC 主动来问的射频配置集序号。
	 * 第 24 轮实测（冷启动逐个扫描，内核 #83 已修好 AMMS 的 md1drdi 懒加载）：
	 *   idx=5（本节点原来的值）→ 立刻死在 mml1_rf_error_check
	 *                             （para0=para1=0x5，即 ASSERT(idx < 5) 越界）
	 *   idx=0/4                → 死在 digrf_iomux.c（8.0~8.4s）
	 *   idx=1/2/3              → 通过 mml1_rf 检查与 DigRF，一路活到 44s 的
	 *                             MD_BOOT_HS2_FAIL（后续卡点是 CCISM/SCP 胶水）
	 * ⇒ 合法且能推进的是 1/2/3，三者目前表现一致；取中间的 2。
	 */
	md_attr_node {
		compatible = "mediatek,md_attr_node";
		mediatek,md_product_name_model_id = <0x0f0f0f0f>;
		/*
		 * 第 38 轮改回**原厂值 0x5**（出处：notes/ref/pearl-dts-with-cp.bak，
		 * 抄自 stock DT 的 mddriver/md_attr_node）。
		 * 第 24 轮把这里改成 0x2 的那次扫描是在 **AMMS/DRDI 还没跑通** 时做的：
		 * 当时 idx=5 会因"DRDI 表为空"而在 mml1_rf_error_check 里越界断言，
		 * 于是被误判为"非法值"。现在 AMMS 已逐字节验证正确（18 次拷贝、
		 * 812,832 字节全覆盖、15/15 应答），**idx=5 这个组合从未在可用状态下测过**。
		 * 运行时仍可用模块参数 pearl_rf_set_idx=<n> 覆盖（-1 = 用设备树）。
		 */
		mediatek,md_drdi_rf_set_idx = <0x2>;
	};

	/*
	 * MD SIM GPIO mapping - the modem asks the AP for these pin numbers and
	 * levels through CCCI RPC (op 0x4002) right before it sends HS2.
	 * Pin numbers come from the Xiaomi MT6895 OSS vendor cust/pearl.dtsi;
	 * without this node the driver answers -5 and the modem never finishes
	 * its boot handshake.
	 */
	gpio_usage_mapping: gpio_usage_mapping {
		compatible = "mediatek,gpio_usage_mapping";
		GPIO_SIM1_HOT_PLUG = <&pio 42 0>;
		GPIO_SIM2_HOT_PLUG = <&pio 43 0>;
		GPIO_SIM2_SCLK = <&pio 44 0>;
		GPIO_SIM2_SRST = <&pio 45 0>;
		GPIO_SIM2_SIO = <&pio 46 0>;
		GPIO_SIM1_SIO = <&pio 47 0>;
		GPIO_SIM1_SRST = <&pio 48 0>;
		GPIO_SIM1_SCLK = <&pio 49 0>;
	};
};

/* 4.2V input rail for the external MT6319 CPU and charge-pump PMICs. */
/ {
	pp4200: regulator-4v2 {
		compatible = "regulator-fixed";
		regulator-name = "pp4200";
		regulator-always-on;
		regulator-boot-on;
		regulator-min-microvolt = <4200000>;
		regulator-max-microvolt = <4200000>;
	};
};

&spmi {
	mt6319_6: pmic@6 {
		compatible = "mediatek,mt6319-regulator", "mediatek,mt6315-regulator";
		reg = <6 0>;
		pvdd1-supply = <&pp4200>;
		pvdd2-supply = <&pp4200>;
		pvdd3-supply = <&pp4200>;
		pvdd4-supply = <&pp4200>;

		regulators {
			mt6319_6_vbuck1: vbuck1 {
				regulator-name = "mt6319_6_vbuck1";
				regulator-min-microvolt = <300000>;
				regulator-max-microvolt = <1193750>;
				regulator-enable-ramp-delay = <256>;
				regulator-allowed-modes = <0 1 2>;
				regulator-always-on;
			};

			mt6319_6_vbuck3: vbuck3 {
				regulator-name = "mt6319_6_vbuck3";
				regulator-min-microvolt = <300000>;
				regulator-max-microvolt = <1193750>;
				regulator-enable-ramp-delay = <256>;
				regulator-allowed-modes = <0 1 2>;
			};
		};
	};

	mt6319_7: pmic@7 {
		compatible = "mediatek,mt6319-regulator", "mediatek,mt6315-regulator";
		reg = <7 0>;
		pvdd1-supply = <&pp4200>;
		pvdd2-supply = <&pp4200>;
		pvdd3-supply = <&pp4200>;
		pvdd4-supply = <&pp4200>;

		regulators {
			mt6319_7_vbuck1: vbuck1 {
				regulator-name = "mt6319_7_vbuck1";
				regulator-min-microvolt = <300000>;
				regulator-max-microvolt = <1193750>;
				regulator-enable-ramp-delay = <256>;
				regulator-allowed-modes = <0 1 2>;
				regulator-always-on;
			};

			mt6319_7_vbuck3: vbuck3 {
				regulator-name = "mt6319_7_vbuck3";
				regulator-min-microvolt = <300000>;
				regulator-max-microvolt = <1193750>;
				regulator-enable-ramp-delay = <256>;
				regulator-allowed-modes = <0 1 2>;
				regulator-always-on;
			};
		};
	};
};
/*
 * Fast-charge manager.  Consumes the TCPM PPS/APDO power supply and
 * drives the SC8551 charge pumps within the pearl power limits.
 */
/ {
	pearl_cp_manager: cp-manager {
		compatible = "xiaomi,pearl-cp-manager";
		power-supplies = <&mt6375_tcpc>;
		charger-supply = <&pearl_managed_charger>;
		gauge-supply = <&bq28z610>;
		constant-charge-voltage-microvolt = <4450000>;
		constant-charge-voltage-ffc-microvolt = <4550000>;
		topoff-soc-percent = <85>;
		charge-fcc-microamp = <10000000>;
		cable-resistance-milliohm = <350>;
		max-temp-decidegrees = <480>;
		max-vbus-microvolt = <12000000>;
		max-ibus-microamp = <6200000>;
		max-fcc-microamp = <12400000>;
		min-pdo-microvolt = <8000000>;
		max-pdo-microvolt = <11000000>;
		status = "okay";
	};
};

/*
 * Fast-charge pumps.  pearl populates two SC8551A 2:1 charge pumps:
 * i2c9 is the master and i2c7 the slave.  pearlpro uses SC8561 parts at
 * 0x64/0x65 and will get its own nodes once that product is enabled.
 */
&pio {
	sc8551_master_irq: sc8551-master-irq {
		pins_cmd_dat {
			pinmux = <PINMUX_GPIO13__FUNC_GPIO13>;
			input-enable;
			bias-pull-up;
		};
	};

	sc8551_slave_irq: sc8551-slave-irq {
		pins_cmd_dat {
			pinmux = <PINMUX_GPIO14__FUNC_GPIO14>;
			input-enable;
			bias-pull-up;
		};
	};
};

&i2c7 {
	sc8551_slave: charge-pump@66 {
		compatible = "southchip,sc8551-slave";
		reg = <0x66>;
		interrupt-parent = <&pio>;
		interrupts = <14 IRQ_TYPE_EDGE_FALLING>;
		pinctrl-names = "default";
		pinctrl-0 = <&sc8551_slave_irq>;
		status = "okay";
	};
};

&i2c9 {
	sc8551_master: charge-pump@66 {
		compatible = "southchip,sc8551-master";
		reg = <0x66>;
		interrupt-parent = <&pio>;
		interrupts = <13 IRQ_TYPE_EDGE_FALLING>;
		pinctrl-names = "default";
		pinctrl-0 = <&sc8551_master_irq>;
		status = "okay";
	};
};


/*
 * SCP sensor hub. This node has no MMIO resources of its own: the SCP owns
 * the physical ALS (tcs3408) and IMU (lsm6dsoq) and streams samples over IPI,
 * so the transport driver binds here only to pick up the board's sensor
 * mounting description.
 *
 * In the IIO/Android device frame +x is to the right of the screen, +y towards
 * the top and +z out of the screen. The lsm6dsoq package on pearl is mounted
 * rotated 180 degrees about the screen normal relative to that frame, which
 * made portrait report as reverse-portrait and landscape as reverse-landscape,
 * so x and y are negated here.
 */
/ {
	sensor_hub: sensor-hub {
		compatible = "mediatek,scp-sensorhub";
		mount-matrix = "-1", "0", "0",
			       "0", "-1", "0",
			       "0", "0", "1";
	};
};

/* Local USB/OTG bring-up; TCPM owns power direction and current limits. */
#include "mt6895-pearl-usb-tcpm.dtsi"

/*
 * Modem rails, as the vendor mddriver node sets them.  Without these
 * md1_pmic_setting_on() has nothing to program and the MD's RF/DFE blocks run
 * on whatever the bootloader left behind.
 */

/*
 * MT6363 MD/DigRF rails. The vendor keeps these always-on (mt6895.dts) and
 * defines the VSRAM_DIGRF rail (mt6363.dtsi); without VSRAM_DIGRF the DigRF
 * SRAM is unpowered and MODEM's digrf_iomux init asserts, and the MD rails
 * may be off when the modem starts.
 */
&mt6363 {
	regulators {
		mt6363_vsram_digrf: VSRAM_DIGRF {
			regulator-compatible = "VSRAM_DIGRF";
			regulator-name = "mt6363_vsram_digrf";
			regulator-min-microvolt = <400000>;
			regulator-max-microvolt = <1193750>;
			regulator-enable-ramp-delay = <180>;
			regulator-allowed-modes = <0 2>;
		};
	};
};

&mt6363_vbuck1 {
	regulator-always-on;
};

&mt6363_vbuck6 {
	regulator-always-on;
};

&mt6363_vsram_modem {
	regulator-always-on;
};

&mt6363_vsram_digrf {
	regulator-always-on;
};

&mddriver {
	md_vmodem-supply = <&mt6363_vbuck6>;
	md_vmodem = <800000 800000>;
	md_vsram-supply = <&mt6363_vsram_modem>;
	md_vsram = <800000 800000>;
	md_vdigrf-supply = <&mt6363_vbuck1>;
	md_vdigrf = <700000 700000>;
};
